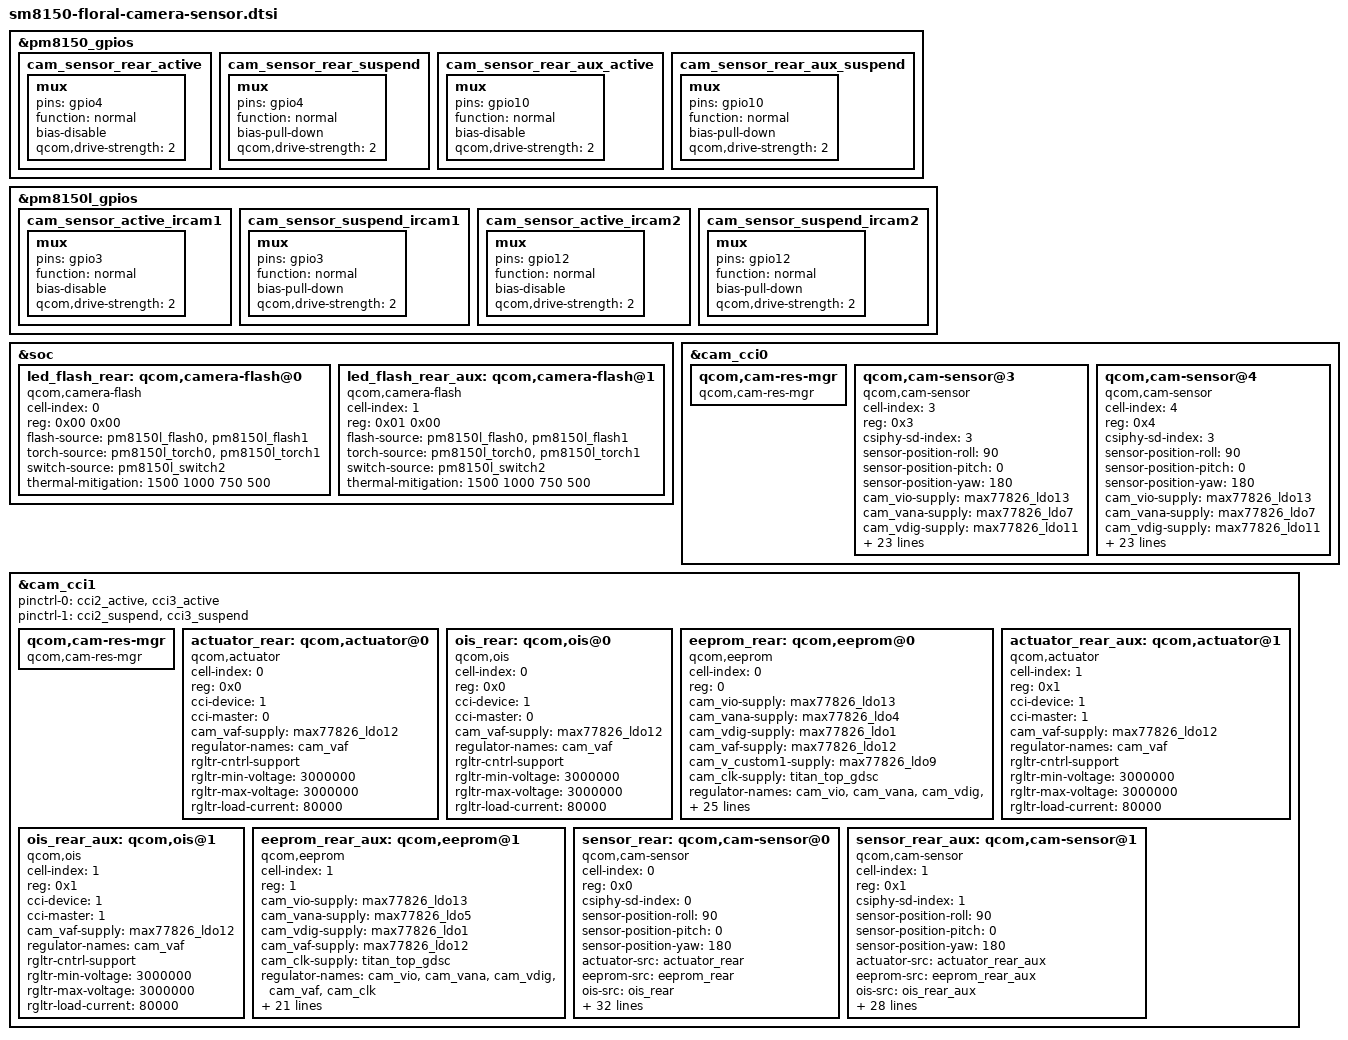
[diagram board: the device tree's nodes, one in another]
/*
* Copyright (c) 2018, The Linux Foundation. All rights reserved.
*
* This program is free software; you can redistribute it and/or modify
* it under the terms of the GNU General Public License version 2 and
* only version 2 as published by the Free Software Foundation.
*
* This program is distributed in the hope that it will be useful,
* but WITHOUT ANY WARRANTY; without even the implied warranty of
* MERCHANTABILITY or FITNESS FOR A PARTICULAR PURPOSE.  See the
* GNU General Public License for more details.
*/

#include <dt-bindings/clock/qcom,camcc-sm8150.h>

&pm8150_gpios {
	cam_sensor_rear_active: cam_sensor_rear_active {
		mux {
			pins = "gpio4";
			function = "normal";
			bias-disable;
			qcom,drive-strength = <2>;
		};
	};

	cam_sensor_rear_suspend: cam_sensor_rear_suspend {
		mux {
			pins = "gpio4";
			function = "normal";
			bias-pull-down;
			qcom,drive-strength = <2>;
		};
	};

	cam_sensor_rear_aux_active: cam_sensor_rear_aux_active {
		mux {
			pins = "gpio10";
			function = "normal";
			bias-disable;
			qcom,drive-strength = <2>;
		};
	};

	cam_sensor_rear_aux_suspend: cam_sensor_rear_aux_suspend {
		mux {
			pins = "gpio10";
			function = "normal";
			bias-pull-down;
			qcom,drive-strength = <2>;
		};
	};
};

&pm8150l_gpios {
	cam_sensor_active_ircam1: cam_sensor_active_ircam1 {
		mux {
			pins = "gpio3";
			function = "normal";
			bias-disable;
			qcom,drive-strength = <2>;
		};
	};

	cam_sensor_suspend_ircam1: cam_sensor_suspend_ircam1 {
		mux {
			pins = "gpio3";
			function = "normal";
			bias-pull-down;
			qcom,drive-strength = <2>;
		};
	};

	cam_sensor_active_ircam2: cam_sensor_active_ircam2 {
		mux {
			pins = "gpio12";
			function = "normal";
			bias-disable;
			qcom,drive-strength = <2>;
		};
	};

	cam_sensor_suspend_ircam2: cam_sensor_suspend_ircam2 {
		mux {
			pins = "gpio12";
			function = "normal";
			bias-pull-down;
			qcom,drive-strength = <2>;
		};
	};
};

&soc {
	led_flash_rear: qcom,camera-flash@0 {
		cell-index = <0>;
		reg = <0x00 0x00>;
		compatible = "qcom,camera-flash";
		flash-source = <&pm8150l_flash0 &pm8150l_flash1>;
		torch-source = <&pm8150l_torch0 &pm8150l_torch1>;
		switch-source = <&pm8150l_switch2>;
		status = "ok";
		thermal-mitigation = <1500 1000 750 500>;
	};

	led_flash_rear_aux: qcom,camera-flash@1 {
		cell-index = <1>;
		reg = <0x01 0x00>;
		compatible = "qcom,camera-flash";
		flash-source = <&pm8150l_flash0 &pm8150l_flash1>;
		torch-source = <&pm8150l_torch0 &pm8150l_torch1>;
		switch-source = <&pm8150l_switch2>;
		status = "ok";
		thermal-mitigation = <1500 1000 750 500>;
	};
};

&cam_cci0 {
	qcom,cam-res-mgr {
		compatible = "qcom,cam-res-mgr";
		status = "ok";
	};

	qcom,cam-sensor@3 {
		cell-index = <3>;
		compatible = "qcom,cam-sensor";
		reg = <0x3>;
		csiphy-sd-index = <3>;
		sensor-position-roll = <90>;
		sensor-position-pitch = <0>;
		sensor-position-yaw = <180>;
		cam_vio-supply = <&max77826_ldo13>;
		cam_vana-supply = <&max77826_ldo7>;
		cam_vdig-supply = <&max77826_ldo11>;
		cam_clk-supply = <&titan_top_gdsc>;
		regulator-names = "cam_vio", "cam_vana", "cam_vdig",
			"cam_clk";
		rgltr-cntrl-support;
		rgltr-min-voltage = <0 2800000 1900000 0>;
		rgltr-max-voltage = <0 2800000 1900000 0>;
		rgltr-load-current = <0 2800000 1900000 0>;
		gpio-no-mux = <0>;
		pinctrl-names = "cam_default", "cam_suspend";
		pinctrl-0 = <&cam_sensor_mclk1_active
				&cam_sensor_active_ircam1>;
		pinctrl-1 = <&cam_sensor_mclk1_suspend
				&cam_sensor_suspend_ircam1>;
		gpios = <&tlmm 14 0>,
			<&pm8150l_gpios 3 0>;
		gpio-reset = <1>;
		gpio-req-tbl-num = <0 1>;
		gpio-req-tbl-flags = <1 0>;
		gpio-req-tbl-label = "CAMIF_MCLK3",
			"CAM_RESET3";
		sensor-mode = <0>;
		cci-device = <0>;
		cci-master = <0>;
		status = "ok";
		clocks = <&clock_camcc CAM_CC_MCLK1_CLK>;
		clock-names = "cam_clk";
		clock-cntl-level = "turbo";
		clock-rates = <24000000>;
	};

	qcom,cam-sensor@4 {
		cell-index = <4>;
		compatible = "qcom,cam-sensor";
		reg = <0x4>;
		csiphy-sd-index = <3>;
		sensor-position-roll = <90>;
		sensor-position-pitch = <0>;
		sensor-position-yaw = <180>;
		cam_vio-supply = <&max77826_ldo13>;
		cam_vana-supply = <&max77826_ldo7>;
		cam_vdig-supply = <&max77826_ldo11>;
		cam_clk-supply = <&titan_top_gdsc>;
		regulator-names = "cam_vio", "cam_vana", "cam_vdig",
			"cam_clk";
		rgltr-cntrl-support;
		rgltr-min-voltage = <0 2800000 1900000 0>;
		rgltr-max-voltage = <0 2800000 1900000 0>;
		rgltr-load-current = <0 2800000 1900000 0>;
		gpio-no-mux = <0>;
		pinctrl-names = "cam_default", "cam_suspend";
		pinctrl-0 = <&cam_sensor_mclk1_active
				&cam_sensor_active_ircam2>;
		pinctrl-1 = <&cam_sensor_mclk1_suspend
				&cam_sensor_suspend_ircam2>;
		gpios = <&tlmm 14 0>,
			<&pm8150l_gpios 12 0>;
		gpio-reset = <1>;
		gpio-req-tbl-num = <0 1>;
		gpio-req-tbl-flags = <1 0>;
		gpio-req-tbl-label = "CAMIF_MCLK4",
			"CAM_RESET4";
		sensor-mode = <0>;
		cci-device = <0>;
		cci-master = <1>;
		status = "ok";
		clocks = <&clock_camcc CAM_CC_MCLK1_CLK>;
		clock-names = "cam_clk";
		clock-cntl-level = "turbo";
		clock-rates = <24000000>;
	};
};

&cam_cci1 {
	pinctrl-0 = <&cci2_active &cci3_active>;
	pinctrl-1 = <&cci2_suspend &cci3_suspend>;

	qcom,cam-res-mgr {
		compatible = "qcom,cam-res-mgr";
		status = "ok";
	};

	actuator_rear: qcom,actuator@0 {
		cell-index = <0>;
		reg = <0x0>;
		compatible = "qcom,actuator";
		cci-device = <1>;
		cci-master = <0>;
		cam_vaf-supply = <&max77826_ldo12>;
		regulator-names = "cam_vaf";
		rgltr-cntrl-support;
		rgltr-min-voltage = <3000000>;
		rgltr-max-voltage = <3000000>;
		rgltr-load-current = <80000>;
	};

	ois_rear: qcom,ois@0 {
		cell-index = <0>;
		reg = <0x0>;
		compatible = "qcom,ois";
		cci-device = <1>;
		cci-master = <0>;
		cam_vaf-supply = <&max77826_ldo12>;
		regulator-names = "cam_vaf";
		rgltr-cntrl-support;
		rgltr-min-voltage = <3000000>;
		rgltr-max-voltage = <3000000>;
		rgltr-load-current = <80000>;
	};

	eeprom_rear: qcom,eeprom@0 {
		cell-index = <0>;
		reg = <0>;
		compatible = "qcom,eeprom";
		cam_vio-supply = <&max77826_ldo13>;
		cam_vana-supply = <&max77826_ldo4>;
		cam_vdig-supply = <&max77826_ldo1>;
		cam_vaf-supply = <&max77826_ldo12>;
		cam_v_custom1-supply = <&max77826_ldo9>;
		cam_clk-supply = <&titan_top_gdsc>;
		regulator-names = "cam_vio", "cam_vana", "cam_vdig",
			"cam_v_custom1", "cam_vaf", "cam_clk";
		rgltr-cntrl-support;
		rgltr-min-voltage = <0 2850000 1100000 1850000 3000000 0>;
		rgltr-max-voltage = <0 2850000 1100000 1850000 3000000 0>;
		rgltr-load-current = <0 80000 105000 80000 80000 0>;
		gpio-no-mux = <0>;
		pinctrl-names = "cam_default", "cam_suspend";
		pinctrl-0 = <&cam_sensor_mclk2_active
				&cam_sensor_rear_active>;
		pinctrl-1 = <&cam_sensor_mclk2_suspend
				&cam_sensor_rear_suspend>;
		gpios = <&tlmm 15 0>,
				<&pm8150_gpios 4 0>;
		gpio-reset = <1>;
		gpio-req-tbl-num = <0 1>;
		gpio-req-tbl-flags = <1 0>;
		gpio-req-tbl-label = "CAMIF_MCLK0",
			"CAM_RESET0";
		sensor-position = <0>;
		sensor-mode = <0>;
		cci-device = <1>;
		cci-master = <0>;
		status = "ok";
		clocks = <&clock_camcc CAM_CC_MCLK2_CLK>;
		clock-names = "cam_clk";
		clock-cntl-level = "turbo";
		clock-rates = <24000000>;
	};

	actuator_rear_aux: qcom,actuator@1 {
		cell-index = <1>;
		reg = <0x1>;
		compatible = "qcom,actuator";
		cci-device = <1>;
		cci-master = <1>;
		cam_vaf-supply = <&max77826_ldo12>;
		regulator-names = "cam_vaf";
		rgltr-cntrl-support;
		rgltr-min-voltage = <3000000>;
		rgltr-max-voltage = <3000000>;
		rgltr-load-current = <80000>;
	};

	ois_rear_aux: qcom,ois@1 {
		cell-index = <1>;
		reg = <0x1>;
		compatible = "qcom,ois";
		cci-device = <1>;
		cci-master = <1>;
		cam_vaf-supply = <&max77826_ldo12>;
		regulator-names = "cam_vaf";
		rgltr-cntrl-support;
		rgltr-min-voltage = <3000000>;
		rgltr-max-voltage = <3000000>;
		rgltr-load-current = <80000>;
	};

	eeprom_rear_aux: qcom,eeprom@1 {
		cell-index = <1>;
		reg = <1>;
		compatible = "qcom,eeprom";
		cam_vio-supply = <&max77826_ldo13>;
		cam_vana-supply = <&max77826_ldo5>;
		cam_vdig-supply = <&max77826_ldo1>;
		cam_vaf-supply = <&max77826_ldo12>;
		cam_clk-supply = <&titan_top_gdsc>;
		regulator-names = "cam_vio", "cam_vana", "cam_vdig",
			"cam_vaf", "cam_clk";
		rgltr-cntrl-support;
		rgltr-min-voltage = <0 2850000 1100000 3000000 0>;
		rgltr-max-voltage = <0 2850000 1100000 3000000 0>;
		rgltr-load-current = <0 80000 105000 80000 0>;
		gpio-no-mux = <0>;
		pinctrl-names = "cam_default", "cam_suspend";
		pinctrl-0 = <&cam_sensor_mclk2_active
			&cam_sensor_rear_aux_active>;
		pinctrl-1 = <&cam_sensor_mclk2_suspend
			&cam_sensor_rear_aux_suspend>;
		gpios = <&tlmm 15 0>,
		<&pm8150_gpios 10 0>;
		gpio-reset = <1>;
		gpio-req-tbl-num = <0 1>;
		gpio-req-tbl-flags = <1 0>;
		gpio-req-tbl-label = "CAMIF_MCLK1",
			"CAM_RESET1";
		sensor-position = <1>;
		sensor-mode = <0>;
		cci-device = <1>;
		cci-master = <1>;
		status = "ok";
		clocks = <&clock_camcc CAM_CC_MCLK2_CLK>;
		clock-names = "cam_clk";
		clock-cntl-level = "turbo";
		clock-rates = <24000000>;
	};

	sensor_rear: qcom,cam-sensor@0 {
		cell-index = <0>;
		compatible = "qcom,cam-sensor";
		reg = <0x0>;
		csiphy-sd-index = <0>;
		sensor-position-roll = <90>;
		sensor-position-pitch = <0>;
		sensor-position-yaw = <180>;
		actuator-src = <&actuator_rear>;
		eeprom-src = <&eeprom_rear>;
		ois-src = <&ois_rear>;
		led-flash-src = <&led_flash_rear>;
		cam_vio-supply = <&max77826_ldo13>;
		cam_vana-supply = <&max77826_ldo4>;
		cam_vdig-supply = <&max77826_ldo1>;
		cam_vaf-supply = <&max77826_ldo12>;
		cam_v_custom1-supply = <&max77826_ldo9>;
		cam_clk-supply = <&titan_top_gdsc>;
		regulator-names = "cam_vio", "cam_vana", "cam_vdig",
			"cam_v_custom1", "cam_vaf", "cam_clk";
		rgltr-cntrl-support;
		rgltr-min-voltage = <0 2825000 1100000 1850000 3000000 0>;
		rgltr-max-voltage = <0 2825000 1100000 1850000 3000000 0>;
		rgltr-load-current = <0 80000 105000 80000 80000 0>;
		gpio-no-mux = <0>;
		pinctrl-names = "cam_default", "cam_suspend";
		pinctrl-0 = <&cam_sensor_mclk2_active
			&cam_sensor_rear_active>;
		pinctrl-1 = <&cam_sensor_mclk2_suspend
			&cam_sensor_rear_suspend>;
		gpios = <&tlmm 15 0>,
			<&pm8150_gpios 4 0>;
		gpio-reset = <1>;
		gpio-req-tbl-num = <0 1>;
		gpio-req-tbl-flags = <1 0>;
		gpio-req-tbl-label = "CAMIF_MCLK0",
			"CAM_RESET0";
		sensor-mode = <0>;
		cci-device = <1>;
		cci-master = <0>;
		status = "ok";
		clocks = <&clock_camcc CAM_CC_MCLK2_CLK>;
		clock-names = "cam_clk";
		clock-cntl-level = "turbo";
		clock-rates = <24000000>;
	};

	sensor_rear_aux: qcom,cam-sensor@1 {
		cell-index = <1>;
		compatible = "qcom,cam-sensor";
		reg = <0x1>;
		csiphy-sd-index = <1>;
		sensor-position-roll = <90>;
		sensor-position-pitch = <0>;
		sensor-position-yaw = <180>;
		actuator-src = <&actuator_rear_aux>;
		eeprom-src = <&eeprom_rear_aux>;
		ois-src = <&ois_rear_aux>;
		led-flash-src = <&led_flash_rear_aux>;
		cam_vio-supply  = <&max77826_ldo13>;
		cam_vana-supply = <&max77826_ldo5>;
		cam_vdig-supply = <&max77826_ldo1>;
		cam_vaf-supply = <&max77826_ldo12>;
		cam_clk-supply = <&titan_top_gdsc>;
		regulator-names = "cam_vio", "cam_vana", "cam_vdig",
			"cam_vaf", "cam_clk";
		rgltr-cntrl-support;
		rgltr-min-voltage = <0 2850000 1100000 3000000 0>;
		rgltr-max-voltage = <0 2850000 1100000 3000000 0>;
		rgltr-load-current = <0 80000 105000 80000 0>;
		gpio-no-mux = <0>;
		pinctrl-names = "cam_default", "cam_suspend";
		pinctrl-0 = <&cam_sensor_mclk2_active
			&cam_sensor_rear_aux_active>;
		pinctrl-1 = <&cam_sensor_mclk2_suspend
			&cam_sensor_rear_aux_suspend>;
		gpios = <&tlmm 15 0>,
			<&pm8150_gpios 10 0>;
		gpio-reset = <1>;
		gpio-req-tbl-num = <0 1>;
		gpio-req-tbl-flags = <1 0>;
		gpio-req-tbl-label = "CAMIF_MCLK1",
			"CAM_RESET1";
		sensor-mode = <0>;
		cci-master = <1>;
		cci-device = <1>;
		status = "ok";
		clocks = <&clock_camcc CAM_CC_MCLK2_CLK>;
		clock-names = "cam_clk";
		clock-cntl-level = "turbo";
		clock-rates = <24000000>;
	};
};
